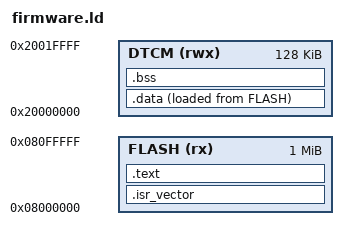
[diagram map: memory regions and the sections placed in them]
ENTRY(Reset_Handler)
MEMORY
{
    FLASH (rx) : ORIGIN = 0x08000000, LENGTH = 1M
    DTCM (rwx) : ORIGIN = 0x20000000, LENGTH = 128K
}
SECTIONS
{
    .isr_vector : { KEEP(*(.isr_vector)) } > FLASH
    .text : { *(.text*) *(.rodata*) . = ALIGN(4); } > FLASH
    .data : {
        . = ALIGN(4); _sdata = .; *(.data*) . = ALIGN(4); _edata = .;
    } > DTCM AT > FLASH
    _sidata = LOADADDR(.data);
    .bss (NOLOAD) : {
        . = ALIGN(4); _sbss = .; *(.bss*) *(COMMON) . = ALIGN(4); _ebss = .;
    } > DTCM
    _stack_top = ORIGIN(DTCM) + LENGTH(DTCM);
    ASSERT(_ebss + 4096 <= _stack_top, "firmware leaves less than 4KiB stack")
}
